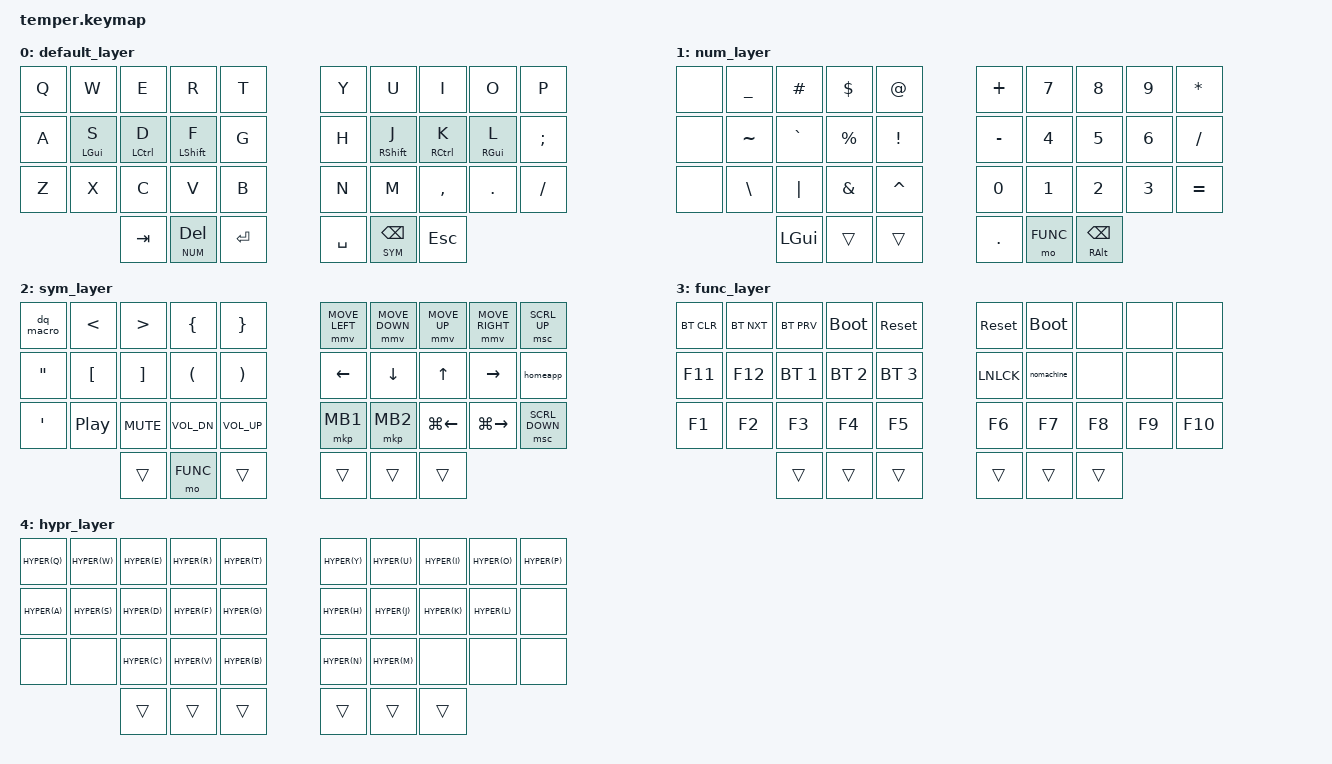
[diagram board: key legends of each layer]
/*
 * Copyright (c) 2020 The ZMK Contributors
 *
 * SPDX-License-Identifier: MIT
 */

#include <behaviors.dtsi>
#include <dt-bindings/zmk/keys.h>
#include <dt-bindings/zmk/bt.h>
#include <dt-bindings/zmk/outputs.h>
#include <dt-bindings/zmk/ext_power.h>
#include <dt-bindings/zmk/pointing.h>
#include <dt-bindings/zmk/reset.h>

#define DEFAULT 0
#define NUM 1
#define SYM 2
#define FUNC 3
#define HYPR 4

#define ______ &trans
#define HYPER(key) &kp LG(LC(LA(LS(key))))

&mt {
  tapping-term-ms = <200>;
  flavor = "tap-preferred";
};

/ {
    behaviors {

        // Home row mods
        hm: homerow_mods {
            compatible = "zmk,behavior-hold-tap";
            #binding-cells = <2>;
            tapping-term-ms = <200>;
            quick-tap-ms = <0>;
            flavor = "tap-preferred";
            bindings = <&kp>, <&kp>;
        };
    };

    /*                KEY POSITIONS
     ╭────────────────────╮ ╭────────────────────╮
     │  0   1   2   3   4 │ │  5   6   7   8   9 │
     │ 10  11  12  13  14 │ │ 15  16  17  18  19 │
     │ 20  21  22  23  24 │ │ 25  26  27  28  29 │
     ╰───────╮ 30  31  32 │ │ 33  34  35╭────────╯
             ╰────────────╯ ╰───────────╯            */

    combos {
        compatible = "zmk,combos";
        // Combo to exit vim (ESC : W Q)
        combo_vimwq {
            timeout-ms = <50>;
            key-positions = <1 2>;
            layers = <DEFAULT>;
            bindings = <&vim_quit>;
        };
        // Combo to MO HYPR layer
        combo_hypr {
            timeout-ms = <50>;
            key-positions = <32 33>;
            layers = <DEFAULT>;
            bindings = <&mo HYPR>;
        };
        // Combo to send CAPS LOCK
        caps_combo {
            timeout-ms = <50>;
            key-positions = <14 15>;
            layers = <DEFAULT>;
            bindings = <&kp CAPS>;
        };
        // Combo to type < > and move cursor left
        lt_gt_combo {
            timeout-ms = <50>;
            key-positions = <1 2>;
            layers = <SYM>;
            bindings = <&lt_gt_macro>;
         };
        // Combo to type { } and move cursor left
        lb_rb_combo {
            timeout-ms = <50>;
            key-positions = <3 4>;
            layers = <SYM>;
            bindings = <&lb_rb_macro>;
        };
        // Combo to type ( ) and move cursor left
        lp_rp_combo {
            timeout-ms = <50>;
            key-positions = <13 14>;
            layers = <SYM>;
            bindings = <&lp_rp_macro>;
        };
        // Combo to type [ ] and move cursor left
        ls_rs_combo {
            timeout-ms = <50>;
            key-positions = <11 12>;
            layers = <SYM>;
            bindings = <&ls_rs_macro>;
        };
     };

    macros {
        // Macro to exit vim: ESC : W Q
        vim_quit: vim_quit {
            compatible = "zmk,behavior-macro";
            #binding-cells = <0>;
            bindings = <&macro_tap &kp ESC &kp COLON &kp W &kp Q &kp ENTER>;
        };
        // Macro to type < > and move cursor left
        lt_gt_macro: lt_gt_macro_with_cursor {
            compatible = "zmk,behavior-macro";
            #binding-cells = <0>;
            bindings = <&macro_tap &kp LT &kp GT &kp LEFT>;
        };
        // Macro to type { } and move cursor left
        lb_rb_macro: lb_rb_macro_with_cursor {
            compatible = "zmk,behavior-macro";
            #binding-cells = <0>;
            bindings = <&macro_tap &kp LBRC &kp RBRC &kp LEFT>;
        };
        // Macro to type ( ) and move cursor left
        lp_rp_macro: lp_rp_macro_with_cursor {
            compatible = "zmk,behavior-macro";
            #binding-cells = <0>;
            bindings = <&macro_tap &kp LPAR &kp RPAR &kp LEFT>;
        };
        // Macro to type [ ] and move cursor left
        ls_rs_macro: ls_rs_macro_with_cursor {
            compatible = "zmk,behavior-macro";
            #binding-cells = <0>;
            bindings = <&macro_tap &kp LBKT &kp RBKT &kp LEFT>;
        };
        // Macro to open homerow app (LGUI+LCTRL+LSHFT) 
        homeapp: homeapp {
            compatible = "zmk,behavior-macro";
            #binding-cells = <0>;
            bindings = <&macro_press &kp LGUI &kp LCTRL &kp LSHFT>,
                        <&macro_release &kp LSHFT &kp LCTRL &kp LGUI>;
        };
        // Macro to type "" and move cursor left
        dq_macro: dq_macro_with_cursor {
            compatible = "zmk,behavior-macro";
            #binding-cells = <0>;
            bindings = <&macro_tap &kp DQT &kp DQT &kp LEFT>;
        };
        nomachine: nomachine_settings {
            compatible = "zmk,behavior-macro";
            #binding-cells = <0>;
            bindings = <&macro_press &kp RCTRL &kp RALT &kp N0>,
                       <&macro_release &kp N0 &kp RALT &kp RCTRL>;
        };
    };

    keymap {
        compatible = "zmk,keymap";

        default_layer {
            bindings = <
// ╭─────────────┬─────────────┬─────────────┬─────────────┬─────────────╮   ╭─────────────┬─────────────┬─────────────┬─────────────┬─────────────╮
        &kp Q       &kp W         &kp E          &kp R          &kp T             &kp Y         &kp U         &kp I         &kp O       &kp P
// ├─────────────┼─────────────┼─────────────┼─────────────┼─────────────┤   ├─────────────┼─────────────┼─────────────┼─────────────┼─────────────┤
        &kp A       &hm LGUI S   &hm LCTRL D     &hm LSHFT F    &kp G             &kp H       &hm RSHFT J   &hm RCTRL K   &hm RGUI L    &kp SEMI
// ├─────────────┼─────────────┼─────────────┼─────────────┼─────────────┤   ├─────────────┼─────────────┼─────────────┼─────────────┼─────────────┤
        &kp Z       &kp X         &kp C         &kp V         &kp B             &kp N         &kp M         &kp COMMA     &kp DOT       &kp FSLH
// ╰─────────────┴─────────────┼─────────────┼─────────────┼─────────────┤   ├─────────────┼─────────────┼─────────────┼─────────────┴─────────────╯
                                    &kp TAB     &lt NUM DEL    &kp ENTER        &kp SPACE    &lt SYM BSPC     &kp ESC
//                             ╰─────────────┴─────────────┴─────────────╯   ╰─────────────┴─────────────┴─────────────╯
            >;
        };
        num_layer {
            bindings = <
// ╭─────────────┬─────────────┬─────────────┬─────────────┬─────────────╮   ╭─────────────┬─────────────┬─────────────┬─────────────┬─────────────╮
       &none        &kp UNDER     &kp HASH      &kp DLLR     &kp AT            &kp PLUS       &kp N7        &kp N8       &kp N9       &kp STAR
// ├─────────────┼─────────────┼─────────────┼─────────────┼─────────────┤   ├─────────────┼─────────────┼─────────────┼─────────────┼─────────────┤
       &none        &kp TILDE     &kp GRAVE     &kp PRCNT    &kp EXCL          &kp MINUS      &kp N4        &kp N5       &kp N6       &kp SLASH
// ├─────────────┼─────────────┼─────────────┼─────────────┼─────────────┤   ├─────────────┼─────────────┼─────────────┼─────────────┼─────────────┤
       &none        &kp BSLH      &kp PIPE      &kp AMPS     &kp CARET         &kp N0         &kp N1        &kp N2       &kp N3       &kp EQUAL
// ╰─────────────┴─────────────┼─────────────┼─────────────┼─────────────┤   ├─────────────┼─────────────┼─────────────┼─────────────┴─────────────╯
                                  &kp LGUI      ______         ______          &kp DOT        &mo FUNC    &mt RALT BSPC
//                             ╰─────────────┴─────────────┴─────────────╯   ╰─────────────┴─────────────┴─────────────╯
            >;
        };
        sym_layer {
            bindings = <
// ╭─────────────┬─────────────┬─────────────┬─────────────┬─────────────╮   ╭─────────────┬─────────────┬─────────────┬─────────────┬─────────────╮
      &dq_macro      &kp LT       &kp GT         &kp LBRC      &kp RBRC        &mmv MOVE_LEFT  &mmv MOVE_DOWN &mmv MOVE_UP  &mmv MOVE_RIGHT  &msc SCRL_UP
// ├─────────────┼─────────────┼─────────────┼─────────────┼─────────────┤   ├─────────────┼─────────────┼─────────────┼─────────────┼─────────────┤
      &kp DQT      &kp LBKT     &kp RBKT       &kp LPAR      &kp RPAR         &kp LEFT        &kp DOWN     &kp UP       &kp RIGHT     &homeapp
// ├─────────────┼─────────────┼─────────────┼─────────────┼─────────────┤   ├─────────────┼─────────────┼─────────────┼─────────────┼─────────────┤
      &kp SQT     &kp C_PP     &kp C_MUTE  &kp C_VOL_DN   &kp C_VOL_UP       &mkp MB1      &mkp MB2     &kp LG(LEFT)  &kp LG(RIGHT)  &msc SCRL_DOWN
// ╰─────────────┴─────────────┼─────────────┼─────────────┼─────────────┤   ├─────────────┼─────────────┼─────────────┼─────────────┴─────────────╯
                                   ______       &mo FUNC        ______          ______        ______        ______
//                             ╰─────────────┴─────────────┴─────────────╯   ╰─────────────┴─────────────┴─────────────╯
            >;
        };

        func_layer {
            bindings = <
// ╭─────────────┬─────────────┬─────────────┬─────────────┬─────────────╮   ╭─────────────┬─────────────┬─────────────┬─────────────┬─────────────╮
     &bt BT_CLR    &bt BT_NXT    &bt BT_PRV    &bootloader   &sys_reset       &sys_reset    &bootloader    &none         &none         &none
// ├─────────────┼─────────────┼─────────────┼─────────────┼─────────────┤   ├─────────────┼─────────────┼─────────────┼─────────────┼─────────────┤
       &kp F11       &kp F12    &bt BT_SEL 1   &bt BT_SEL 2  &bt BT_SEL 3       &kp LNLCK     &nomachine    &none         &none         &none
// ├─────────────┼─────────────┼─────────────┼─────────────┼─────────────┤   ├─────────────┼─────────────┼─────────────┼─────────────┼─────────────┤
       &kp F1        &kp F2        &kp F3        &kp F4        &kp F5           &kp F6         &kp F7       &kp F8        &kp F9         &kp F10
// ╰─────────────┴─────────────┼─────────────┼─────────────┼─────────────┤   ├─────────────┼─────────────┼─────────────┼─────────────┴─────────────╯
                                   ______        ______        ______            ______        ______        ______
//                             ╰─────────────┴─────────────┴─────────────╯   ╰─────────────┴─────────────┴─────────────╯
            >;
        };

        hypr_layer {
            bindings = <
// ╭─────────────┬─────────────┬─────────────┬─────────────┬─────────────╮   ╭─────────────┬─────────────┬─────────────┬─────────────┬─────────────╮
     HYPER(Q)       HYPER(W)       HYPER(E)      HYPER(R)      HYPER(T)         HYPER(Y)       HYPER(U)     HYPER(I)       HYPER(O)      HYPER(P)
// ├─────────────┼─────────────┼─────────────┼─────────────┼─────────────┤   ├─────────────┼─────────────┼─────────────┼─────────────┼─────────────┤
     HYPER(A)       HYPER(S)       HYPER(D)      HYPER(F)      HYPER(G)         HYPER(H)       HYPER(J)     HYPER(K)       HYPER(L)      &none
// ├─────────────┼─────────────┼─────────────┼─────────────┼─────────────┤   ├─────────────┼─────────────┼─────────────┼─────────────┼─────────────┤
       &none         &none         HYPER(C)      HYPER(V)      HYPER(B)         HYPER(N)       HYPER(M)      &none         &none         &none
// ╰─────────────┴─────────────┼─────────────┼─────────────┼─────────────┤   ├─────────────┼─────────────┼─────────────┼─────────────┴─────────────╯
                                    ______        ______        ______            ______        ______        ______
//                             ╰─────────────┴─────────────┴─────────────╯   ╰─────────────┴─────────────┴─────────────╯
            >;
        };
    };
};
